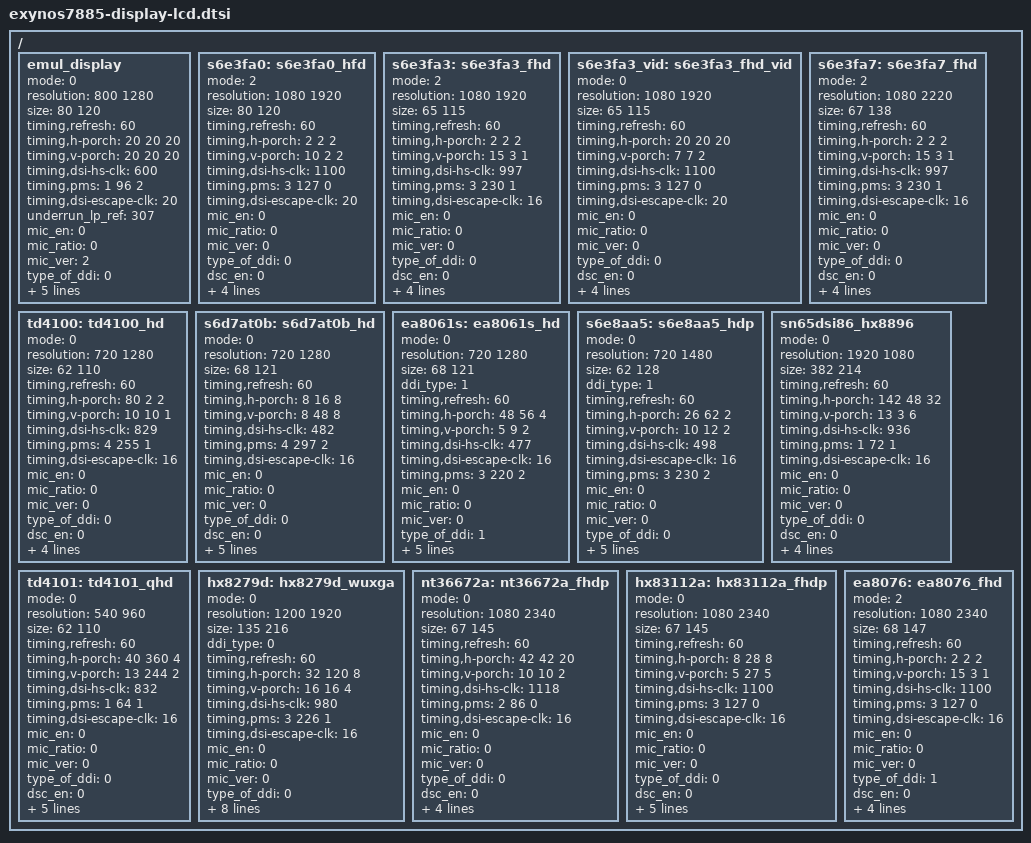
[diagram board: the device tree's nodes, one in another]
/*
 * SAMSUNG LCD Panel Device Tree Source
 *
 * Copyright (c) 2016 Samsung Electronics Co., Ltd.
 *		http://www.samsung.com
 *
 * This program is free software; you can redistribute it and/or modify
 * it under the terms of the GNU General Public License version 2 as
 * published by the Free Software Foundation.
*/

/ {
	emul_display: emul_display {
		mode = <0>; /* 0: video mode, 1: DP command mode, 2: MIPI command mode */
		resolution = <800 1280>;
		size = <80 120>;
		timing,refresh = <60>;
		timing,h-porch = <20 20 20>;
		timing,v-porch = <20 20 20>;
		timing,dsi-hs-clk = <600>;
		/* TODO : pms value to be set */
		timing,pms = <1 96 2>;
		timing,dsi-escape-clk = <20>;
		underrun_lp_ref = <307>;
		mic_en = <0>;		/* 0: Disable, 1: Enable */
		mic_ratio = <0>;	/* 0: 1/2 mic, 1: 1/3 mic */
		mic_ver = <2>;		/* 0: mic v1.1, 1: v1.2, 2: v2.0 */
		type_of_ddi = <0>;	/* 0: Samsung Mobile, 1: MAGNA, 2: Normal(Etc) */
		dsc_en = <0>;		/* 0: Disable, 1: Enable */
		dsc_cnt = <0>;		/* used DSC count */
		dsc_slice_num = <0>;	/* count of dsc slice */
		data_lane = <4>;	/* number of using data lane */
		vt_compensation = <2871>;	/* for difference between wordclk and vclk at video mode */
	};

	s6e3fa0: s6e3fa0_hfd {
		mode = <2>; /* 0: video mode, 1: DP command mode, 2: MIPI command mode */
		resolution = <1080 1920>;
		size = <80 120>;
		timing,refresh = <60>;
		timing,h-porch = <2 2 2>;
		timing,v-porch = <10 2 2>;
		timing,dsi-hs-clk = <1100>;
		/* TODO : pms value to be set */
		timing,pms = <3 127 0>;
		timing,dsi-escape-clk = <20>;
		mic_en = <0>;		/* 0: Disable, 1: Enable */
		mic_ratio = <0>;	/* 0: 1/2 mic, 1: 1/3 mic */
		mic_ver = <0>;		/* 0: mic v1.1, 1: v1.2, 2: v2.0 */
		type_of_ddi = <0>;	/* 0: Samsung Mobile, 1: MAGNA, 2: Normal(Etc) */
		dsc_en = <0>;		/* 0: Disable, 1: Enable */
		dsc_cnt = <0>;		/* used DSC count */
		dsc_slice_num = <0>;	/* count of dsc slice */
		data_lane = <4>;	/* number of using data lane */
		cmd_underrun_lp_ref = <4942>;	/* for underrun detect at command mode */
	};

	s6e3fa3: s6e3fa3_fhd {
		mode = <2>; /* 0: video mode, 1: DP command mode, 2: MIPI command mode */
		resolution = <1080 1920>;
		size = <65 115>;
		timing,refresh = <60>;
		timing,h-porch = <2 2 2>;
		timing,v-porch = <15 3 1>;
		timing,dsi-hs-clk = <997>;
		timing,pms = <3 230 1>;
		timing,dsi-escape-clk = <16>;
		mic_en = <0>;		/* 0: Disable, 1: Enable */
		mic_ratio = <0>;	/* 0: 1/2 mic, 1: 1/3 mic */
		mic_ver = <0>;		/* 0: mic v1.1, 1: v1.2, 2: v2.0 */
		type_of_ddi = <0>;	/* 0: Samsung Mobile, 1: MAGNA, 2: Normal(Etc) */
		dsc_en = <0>;		/* 0: Disable, 1: Enable */
		dsc_cnt = <0>;		/* used DSC count */
		dsc_slice_num = <0>;	/* count of dsc slice */
		data_lane = <4>;	/* number of using data lane */
		cmd_underrun_lp_ref = <4942>;	/* for underrun detect at command mode */
	};

	s6e3fa3_vid: s6e3fa3_fhd_vid {
		mode = <0>; /* 0: video mode, 1: DP command mode, 2: MIPI command mode */
		resolution = <1080 1920>;
		size = <65 115>;
		timing,refresh = <60>;
		timing,h-porch = <20 20 20>;
		timing,v-porch = <7 7 2>;
		timing,dsi-hs-clk = <1100>;
		/* TODO : pms value to be set */
		timing,pms = <3 127 0>;
		timing,dsi-escape-clk = <20>;
		mic_en = <0>;		/* 0: Disable, 1: Enable */
		mic_ratio = <0>;	/* 0: 1/2 mic, 1: 1/3 mic */
		mic_ver = <0>;		/* 0: mic v1.1, 1: v1.2, 2: v2.0 */
		type_of_ddi = <0>;	/* 0: Samsung Mobile, 1: MAGNA, 2: Normal(Etc) */
		dsc_en = <0>;		/* 0: Disable, 1: Enable */
		dsc_cnt = <0>;		/* used DSC count */
		dsc_slice_num = <0>;	/* count of dsc slice */
		data_lane = <4>;	/* number of using data lane */
		vt_compensation = <1284>;	/* for difference between wordclk and vclk at video mode */
	};

	s6e3fa7: s6e3fa7_fhd {
		mode = <2>; /* 0: video mode, 1: DP command mode, 2: MIPI command mode */
		resolution = <1080 2220>;
		size = <67 138>;	/* 67.176 x 138.084 */
		timing,refresh = <60>;
		timing,h-porch = <2 2 2>;
		timing,v-porch = <15 3 1>;
		timing,dsi-hs-clk = <997>;
		timing,pms = <3 230 1>;
		timing,dsi-escape-clk = <16>;
		mic_en = <0>;		/* 0: Disable, 1: Enable */
		mic_ratio = <0>;	/* 0: 1/2 mic, 1: 1/3 mic */
		mic_ver = <0>;		/* 0: mic v1.1, 1: v1.2, 2: v2.0 */
		type_of_ddi = <0>;	/* 0: Samsung Mobile, 1: MAGNA, 2: Normal(Etc) */
		dsc_en = <0>;		/* 0: Disable, 1: Enable */
		dsc_cnt = <0>;		/* used DSC count */
		dsc_slice_num = <0>;	/* count of dsc slice */
		data_lane = <4>;	/* number of using data lane */
		cmd_underrun_lp_ref = <2498>;	/* for underrun detect at command mode */
	};

	td4100: td4100_hd {
		mode = <0>; /* 0: video mode, 1: DP command mode, 2: MIPI command mode */
		resolution = <720 1280>;
		size = <62 110>;
		timing,refresh = <60>;
		timing,h-porch = <80 2 2>;
		timing,v-porch = <10 10 1>;
		timing,dsi-hs-clk = <829>;
		timing,pms = <4 255 1>;
		timing,dsi-escape-clk = <16>;
		mic_en = <0>;		/* 0: Disable, 1: Enable */
		mic_ratio = <0>;	/* 0: 1/2 mic, 1: 1/3 mic */
		mic_ver = <0>;		/* 0: mic v1.1, 1: v1.2, 2: v2.0 */
		type_of_ddi = <0>;	/* 0: Samsung Mobile, 1: MAGNA, 2: Normal(Etc) */
		dsc_en = <0>;		/* 0: Disable, 1: Enable */
		dsc_cnt = <0>;		/* used DSC count */
		dsc_slice_num = <0>;	/* count of dsc slice */
		data_lane = <4>;	/* number of using data lane */
		vt_compensation = <1851>;	/* for difference between wordclk and vclk at video mode */
	};

	s6d7at0b: s6d7at0b_hd {
		mode = <0>; /* 0: video mode, 1: DP command mode, 2: MIPI command mode */
		resolution = <720 1280>;
		size = <68 121>;
		timing,refresh = <60>;
		timing,h-porch = <8 16 8>;
		timing,v-porch = <8 48 8>;
		timing,dsi-hs-clk = <482>;
		timing,pms = <4 297 2>;
		timing,dsi-escape-clk = <16>;
		mic_en = <0>;		/* 0: Disable, 1: Enable */
		mic_ratio = <0>;	/* 0: 1/2 mic, 1: 1/3 mic */
		mic_ver = <0>;		/* 0: mic v1.1, 1: v1.2, 2: v2.0 */
		type_of_ddi = <0>;	/* 0: Samsung Mobile, 1: MAGNA, 2: Normal(Etc) */
		dsc_en = <0>;		/* 0: Disable, 1: Enable */
		dsc_cnt = <0>;		/* used DSC count */
		dsc_slice_num = <0>;	/* count of dsc slice */
		data_lane = <4>;	/* number of using data lane */
		vt_compensation = <742>;	/* for difference between wordclk and vclk at video mode */
		clklane_onoff = <1>;
	};

	ea8061s: ea8061s_hd {
		mode = <0>;
		resolution = <720 1280>;
		size = <68 121>;
		ddi_type = <1>;
		timing,refresh = <60>;
		/* HBP HFP HSW */
		timing,h-porch = <48 56 4>;
		/* VBP VFP VSW */
		timing,v-porch = <5 9 2>;
		timing,dsi-hs-clk = <477>;
		timing,dsi-escape-clk = <16>;
		timing,pms = <3 220 2>;
		mic_en = <0>;		/* 0: Disable, 1: Enable */
		mic_ratio = <0>;	/* 0: 1/2 mic, 1: 1/3 mic */
		mic_ver = <0>;		/* 0: mic v1.1, 1: v1.2, 2: v2.0 */
		type_of_ddi = <1>;	/* 0: Samsung Mobile, 1: MAGNA, 2: Normal(Etc) */
		dsc_en = <0>;		/* 0: Disable, 1: Enable */
		dsc_cnt = <0>;		/* used DSC count */
		dsc_slice_num = <0>;	/* count of dsc slice */
		data_lane = <4>;	/* number of using data lane */

		vt_compensation = <706>;	/* for difference between wordclk and vclk at video mode */
	};

	s6e8aa5: s6e8aa5_hdp {
		mode = <0>;
		resolution = <720 1480>;
		size = <62 128>;	/* 62.35 x 128.17 */
		ddi_type = <1>;
		timing,refresh = <60>;
		/* HBP HFP HSW */
		timing,h-porch = <26 62 2>;
		/* VBP VFP VSW */
		timing,v-porch = <10 12 2>;
		timing,dsi-hs-clk = <498>;
		timing,dsi-escape-clk = <16>;
		timing,pms = <3 230 2>;
		mic_en = <0>;		/* 0: Disable, 1: Enable */
		mic_ratio = <0>;	/* 0: 1/2 mic, 1: 1/3 mic */
		mic_ver = <0>;		/* 0: mic v1.1, 1: v1.2, 2: v2.0 */
		type_of_ddi = <0>;	/* 0: Samsung Mobile, 1: MAGNA, 2: Normal(Etc) */
		dsc_en = <0>;		/* 0: Disable, 1: Enable */
		dsc_cnt = <0>;		/* used DSC count */
		dsc_slice_num = <0>;	/* count of dsc slice */
		data_lane = <4>;	/* number of using data lane */

		vt_compensation = <570>;	/* for difference between wordclk and vclk at video mode */
	};

	sn65dsi86_hx8896: sn65dsi86_hx8896 {
		mode = <0>; /* 0: video mode, 1: DP command mode, 2: MIPI command mode */
		resolution = <1920 1080>;
		size = <382 214>;	/* 381.888(H) x 213.812(V) */
		timing,refresh = <60>;
		/* HBP HFP HSW */
		timing,h-porch = <142 48 32>;
		/* VBP VFP VSW */
		timing,v-porch = <13 3 6>;
		timing,dsi-hs-clk = <936>;
		timing,pms = <1 72 1>;
		timing,dsi-escape-clk = <16>;
		mic_en = <0>;		/* 0: Disable, 1: Enable */
		mic_ratio = <0>;	/* 0: 1/2 mic, 1: 1/3 mic */
		mic_ver = <0>;		/* 0: mic v1.1, 1: v1.2, 2: v2.0 */
		type_of_ddi = <0>;	/* 0: Samsung Mobile, 1: MAGNA, 2: Normal(Etc) */
		dsc_en = <0>;		/* 0: Disable, 1: Enable */
		dsc_cnt = <0>;		/* used DSC count */
		dsc_slice_num = <0>;	/* count of dsc slice */
		data_lane = <4>;	/* number of using data lane */
		vt_compensation = <1397>;	/* for difference between wordclk and vclk at video mode */
	};

	td4101: td4101_qhd {
		mode = <0>; /* 0: video mode, 1: DP command mode, 2: MIPI command mode */
		resolution = <540 960>;
		size = <62 110>;
		timing,refresh = <60>;
		/* dsim H porch : HBP, HFP, HSA */
		timing,h-porch = <40 360 4>;
		/* dsim V porch : VBP, VFP, VSA */
		timing,v-porch = <13 244 2>;
		timing,dsi-hs-clk = <832>;
		timing,pms = <1 64 1>;
		timing,dsi-escape-clk = <16>;
		mic_en = <0>;		/* 0: Disable, 1: Enable */
		mic_ratio = <0>;	/* 0: 1/2 mic, 1: 1/3 mic */
		mic_ver = <0>;		/* 0: mic v1.1, 1: v1.2, 2: v2.0 */
		type_of_ddi = <0>;	/* 0: Samsung Mobile, 1: MAGNA, 2: Normal(Etc) */
		dsc_en = <0>;		/* 0: Disable, 1: Enable */
		dsc_cnt = <0>;		/* used DSC count */
		dsc_slice_num = <0>;	/* count of dsc slice */
		data_lane = <2>;	/* number of using data lane */
		vt_compensation = <1900>;	/* for difference between wordclk and vclk at video mode */
		clklane_onoff = <1>;
	};

	hx8279d: hx8279d_wuxga {
		mode = <0>; /* 0: video mode, 1: DP command mode, 2: MIPI command mode */
		resolution = <1200 1920>;
		size = <135 216>;
		ddi_type = <0>;
		timing,refresh = <60>;
		/* HBP HFP HSW */
		timing,h-porch = <32 120 8>;
		/* VBP VFP VSW */
		timing,v-porch = <16 16 4>;
		timing,dsi-hs-clk = <980>;
		timing,pms = <3 226 1>;
		timing,dsi-escape-clk = <16>;
		mic_en = <0>;		/* 0: Disable, 1: Enable */
		mic_ratio = <0>;	/* 0: 1/2 mic, 1: 1/3 mic */
		mic_ver = <0>;		/* 0: mic v1.1, 1: v1.2, 2: v2.0 */
		type_of_ddi = <0>;	/* 0: Samsung Mobile, 1: MAGNA, 2: Normal(Etc) */
		dsc_en = <0>;		/* 0: Disable, 1: Enable */
		dsc_cnt = <0>;		/* used DSC count */
		dsc_slice_num = <0>;	/* count of dsc slice */
		data_lane = <4>;	/* number of using data lane */
		vt_compensation = <728>;	/* for difference between wordclk and vclk at video mode */
		clklane_onoff = <1>;
		duty_max = <199>;
		duty_outdoor = <255>;
	};

	nt36672a: nt36672a_fhdp {
		mode = <0>; /* 0: video mode, 1: DP command mode, 2: MIPI command mode */
		resolution = <1080 2340>;
		size = <67 145>;
		timing,refresh = <60>;
		/* dsim H porch : HBP, HFP, HSA */
		timing,h-porch = <42 42 20>;
		/* dsim V porch : VBP, VFP, VSA */
		timing,v-porch = <10 10 2>;
		timing,dsi-hs-clk = <1118>;
		timing,pms = <2 86 0>;
		timing,dsi-escape-clk = <16>;
		mic_en = <0>;		/* 0: Disable, 1: Enable */
		mic_ratio = <0>;	/* 0: 1/2 mic, 1: 1/3 mic */
		mic_ver = <0>;		/* 0: mic v1.1, 1: v1.2, 2: v2.0 */
		type_of_ddi = <0>;	/* 0: Samsung Mobile, 1: MAGNA, 2: Normal(Etc) */
		dsc_en = <0>;		/* 0: Disable, 1: Enable */
		dsc_cnt = <0>;		/* used DSC count */
		dsc_slice_num = <0>;	/* count of dsc slice */
		data_lane = <4>;	/* number of using data lane */
		vt_compensation = <788>;	/* for difference between wordclk and vclk at video mode */
	};

	hx83112a: hx83112a_fhdp {
		mode = <0>; /* 0: video mode, 1: DP command mode, 2: MIPI command mode */
		resolution = <1080 2340>;
		size = <67 145>;
		timing,refresh = <60>;
		/* dsim H porch : HBP, HFP, HSA */
		timing,h-porch = <8 28 8>;
		/* dsim V porch : VBP, VFP, VSA */
		timing,v-porch = <5 27 5>;
		timing,dsi-hs-clk = <1100>;
		timing,pms = <3 127 0>;
		timing,dsi-escape-clk = <16>;
		mic_en = <0>;		/* 0: Disable, 1: Enable */
		mic_ratio = <0>;	/* 0: 1/2 mic, 1: 1/3 mic */
		mic_ver = <0>;		/* 0: mic v1.1, 1: v1.2, 2: v2.0 */
		type_of_ddi = <0>;	/* 0: Samsung Mobile, 1: MAGNA, 2: Normal(Etc) */
		dsc_en = <0>;		/* 0: Disable, 1: Enable */
		dsc_cnt = <0>;		/* used DSC count */
		dsc_slice_num = <0>;	/* count of dsc slice */
		data_lane = <4>;	/* number of using data lane */
		vt_compensation = <804>;	/* for difference between wordclk and vclk at video mode */
		eotp_disabled = <1>;	/* 0:EOTP Enable, 1: EOTP Disable */
	};

	ea8076: ea8076_fhd {
		mode = <2>; /* 0: video mode, 1: DP command mode, 2: MIPI command mode */
		resolution = <1080 2340>;
		size = <68 147>;	/* 67.932 * 147.186 */
		timing,refresh = <60>;
		/* HBP HFP HSW */
		timing,h-porch = <2 2 2>;
		/* VBP VFP VSW */
		timing,v-porch = <15 3 1>;
		timing,dsi-hs-clk = <1100>;
		timing,pms = <3 127 0>;
		timing,dsi-escape-clk = <16>;
		mic_en = <0>;		/* 0: Disable, 1: Enable */
		mic_ratio = <0>;	/* 0: 1/2 mic, 1: 1/3 mic */
		mic_ver = <0>;		/* 0: mic v1.1, 1: v1.2, 2: v2.0 */
		type_of_ddi = <1>;	/* 0: Samsung Mobile, 1: MAGNA, 2: Normal(Etc) */
		dsc_en = <0>;		/* 0: Disable, 1: Enable */
		dsc_cnt = <0>;		/* used DSC count */
		dsc_slice_num = <0>;	/* count of dsc slice */
		data_lane = <4>;	/* number of using data lane */
		cmd_underrun_lp_ref = <3425>;	/* for underrun detect at command mode */
	};
};
